# MKV31F25612 register map
Vendor: Freescale Semiconductor, Inc.; Series: Kinetis_V; File version: 1.6
CPU: CM4 r0p1, little endian, no MPU, FPU, VTOR, 4 interrupt priority bits
Registers are 32-bit, read-write, reset 0x0 unless marked. A register's access mark holds for its fields unless they carry their own. Offsets are from the block's base; [hi:lo] are bit positions; {n}, {i} and the like mark numbered series; 'fields as' and 'values as' point back to an identical list.

## RFSYS — System register file
Base 0x40041000; register names take the prefix RFSYS_
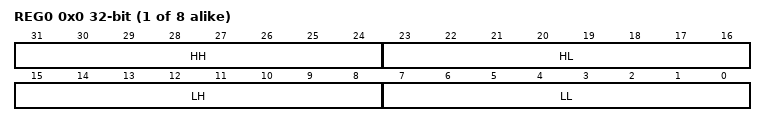
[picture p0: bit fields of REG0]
{0x0+4i} REG{i} (i=0..7) — Register file register
  [31:24] HH — High higher byte
  [23:16] HL — High lower byte
  [15:8] LH — Low higher byte
  [7:0] LL — Low lower byte

## PORTA — Pin Control and Interrupts
Base 0x40049000; register names take the prefix PORTA_
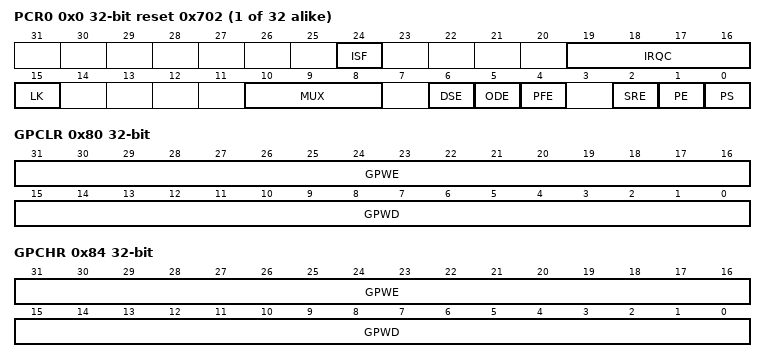
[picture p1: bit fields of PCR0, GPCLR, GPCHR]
{0x0+4i} PCR{i} (i=0..31) reset 0x702 — Pin Control Register n
  [24] ISF — Interrupt Status Flag
    0=Configured interrupt is not detected; 1=Configured interrupt is detected. If the pin is configured to generate a DMA request, then the corresponding flag will be cleared automatically at the completion of the requested DMA transfer. Otherwise, the flag remains set until a logic 1 is written to the flag. If the pin is configured for a level sensitive interrupt and the pin remains asserted, then the flag is set again immediately after it is cleared.
  [19:16] IRQC — Interrupt Configuration
    0=Interrupt/DMA request disabled; 1=DMA request on rising edge; 2=DMA request on falling edge; 3=DMA request on either edge; 8=Interrupt when logic 0; 9=Interrupt on rising-edge; 10=Interrupt on falling-edge; 11=Interrupt on either edge; 12=Interrupt when logic 1
  [15] LK — Lock Register
    0=Pin Control Register fields [15:0] are not locked; 1=Pin Control Register fields [15:0] are locked and cannot be updated until the next system reset
  [10:8] MUX — Pin Mux Control
    0=Pin disabled (analog); 1=Alternative 1 (GPIO); {v}=Alternative {v} (chip-specific) (v=2..7)
  [6] DSE — Drive Strength Enable
    0=Low drive strength is configured on the corresponding pin, if pin is configured as a digital output; 1=High drive strength is configured on the corresponding pin, if pin is configured as a digital output
  [5] ODE — Open Drain Enable
    0=Open drain output is disabled on the corresponding pin; 1=Open drain output is enabled on the corresponding pin, if the pin is configured as a digital output
  [4] PFE — Passive Filter Enable
    0=Passive input filter is disabled on the corresponding pin; 1=Passive input filter is enabled on the corresponding pin, if the pin is configured as a digital input. Refer to the device data sheet for filter characteristics.
  [2] SRE — Slew Rate Enable
    0=Fast slew rate is configured on the corresponding pin, if the pin is configured as a digital output; 1=Slow slew rate is configured on the corresponding pin, if the pin is configured as a digital output
  [1] PE — Pull Enable
    0=Internal pullup or pulldown resistor is not enabled on the corresponding pin; 1=Internal pullup or pulldown resistor is enabled on the corresponding pin, if the pin is configured as a digital input
  [0] PS — Pull Select
    0=Internal pulldown resistor is enabled on the corresponding pin, if the corresponding PE field is set; 1=Internal pullup resistor is enabled on the corresponding pin, if the corresponding PE field is set
0x80 GPCLR wo — Global Pin Control Low Register
  [31:16] GPWE — Global Pin Write Enable
    0=Corresponding Pin Control Register is not updated with the value in GPWD; 1=Corresponding Pin Control Register is updated with the value in GPWD
  [15:0] GPWD — Global Pin Write Data
0x84 GPCHR wo — Global Pin Control High Register
  fields as GPCLR
0xA0 ISFR — Interrupt Status Flag Register
  [31:0] ISF — Interrupt Status Flag
    values as PCR0.ISF

## EWM — External Watchdog Monitor
Base 0x40061000; register names take the prefix EWM_
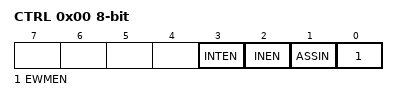
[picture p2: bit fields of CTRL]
0x00 CTRL 8-bit — Control Register
  [3] INTEN — Interrupt Enable.
  [2] INEN — Input Enable.
  [1] ASSIN — EWM_in's Assertion State Select.
  [0] EWMEN — EWM enable.
0x01 SERV 8-bit wo — Service Register
  [7:0] SERVICE — The EWM service mechanism requires the CPU to write two values to the SERV register: a first data byte of 0xB4, followed by a second data byte of 0x2C
0x02 CMPL 8-bit — Compare Low Register
  [7:0] COMPAREL — To prevent runaway code from changing this field, software should write to this field after a CPU reset even if the (default) minimum service time is required
0x03 CMPH 8-bit reset 0xFF — Compare High Register
  [7:0] COMPAREH — To prevent runaway code from changing this field, software should write to this field after a CPU reset even if the (default) maximum service time is required
0x05 CLKPRESCALER 8-bit — Clock Prescaler Register
  [7:0] CLK_DIV — Selected low power source for running the EWM counter can be prescaled as below
